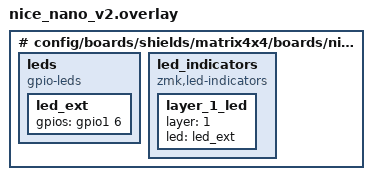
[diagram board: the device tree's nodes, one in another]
# config/boards/shields/matrix4x4/boards/nice_nano_v2.overlay

/*
 * Optional LED configuration for external LEDs
 * Add this file only if you're using the external LED functionality
 */

/ {
    leds {
        compatible = "gpio-leds";
        led_ext: led_ext {
            gpios = <&gpio1 6 GPIO_ACTIVE_HIGH>;
        };
    };

    led_indicators {
        compatible = "zmk,led-indicators";
        layer_1_led {
            layer = <1>;
            led = <&led_ext>;
        };
    };
};
